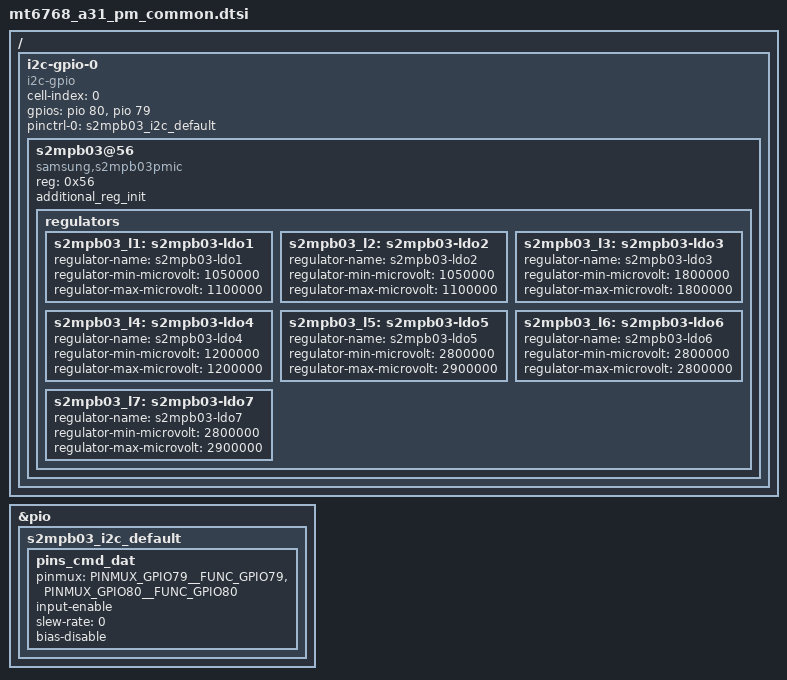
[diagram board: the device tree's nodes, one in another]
/* Copyright (c) 2019, The Linux Foundation. All rights reserved.
 *
 * This program is free software; you can redistribute it and/or modify
 * it under the terms of the GNU General Public License version 2 and
 * only version 2 as published by the Free Software Foundation.
 *
 * This program is distributed in the hope that it will be useful,
 * but WITHOUT ANY WARRANTY; without even the implied warranty of
 * MERCHANTABILITY or FITNESS FOR A PARTICULAR PURPOSE.  See the
 * GNU General Public License for more details.
 */

&pio {
	s2mpb03_i2c_default: s2mpb03_i2c_default {
		pins_cmd_dat {
			pinmux = <PINMUX_GPIO79__FUNC_GPIO79>, <PINMUX_GPIO80__FUNC_GPIO80>;
			input-enable;
			slew-rate = <0>;
			bias-disable;
		};
	};
};

/ {
	fragment@model {
		target-path = "/";
		__overlay__ {
			/* S2MPB03 Camera PMIC */
			i2c-gpio-0 {
				status = "okay";
				cell-index = <0>;
				compatible = "i2c-gpio";
				gpios = <&pio 80 0 /* sda */
					&pio 79 0 /* scl */>;

				pinctrl-names = "default";
				pinctrl-0 = <&s2mpb03_i2c_default>;

				s2mpb03@56 {
					compatible = "samsung,s2mpb03pmic";
					reg = <0x56>;
					additional_reg_init;
					regulators {
						s2mpb03_l1: s2mpb03-ldo1 {	/* RCAM1_DVDD_1P1 */
							regulator-name = "s2mpb03-ldo1";
							regulator-min-microvolt = <1050000>;
							regulator-max-microvolt = <1100000>;
						};
						s2mpb03_l2: s2mpb03-ldo2 {	/* FCAM_DVDD_1P05 */
							regulator-name = "s2mpb03-ldo2";
							regulator-min-microvolt = <1050000>;
							regulator-max-microvolt = <1100000>;
						};
						s2mpb03_l3: s2mpb03-ldo3 {	/* CAM_DVDDIO_1P8 */
							regulator-name = "s2mpb03-ldo3";
							regulator-min-microvolt = <1800000>;
							regulator-max-microvolt = <1800000>;
						};
						s2mpb03_l4: s2mpb03-ldo4 {	/* RCAM3_DVDD_1P2 */
							regulator-name = "s2mpb03-ldo4";
							regulator-min-microvolt = <1200000>;
							regulator-max-microvolt = <1200000>;
						};
						s2mpb03_l5: s2mpb03-ldo5 {	/* RCAM1_AVDD1_2P9 */
							regulator-name = "s2mpb03-ldo5";
							regulator-min-microvolt = <2800000>;
							regulator-max-microvolt = <2900000>;
						};
						s2mpb03_l6: s2mpb03-ldo6 {	/* RCAM2_AVDD_2P8 */
							regulator-name = "s2mpb03-ldo6";
							regulator-min-microvolt = <2800000>;
							regulator-max-microvolt = <2800000>;
						};
						s2mpb03_l7: s2mpb03-ldo7 {	/* FCAM_AVDD_2P9 */
							regulator-name = "s2mpb03-ldo7";
							regulator-min-microvolt = <2800000>;
							regulator-max-microvolt = <2900000>;
						};
					};
				};
			};
		};
	};
};

